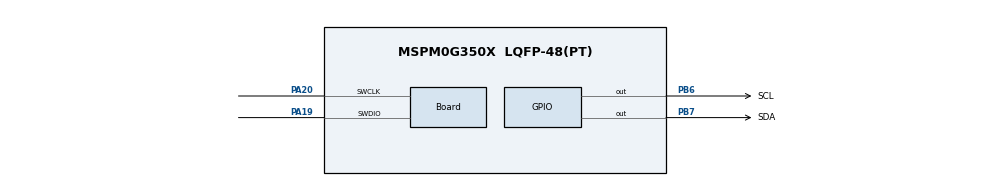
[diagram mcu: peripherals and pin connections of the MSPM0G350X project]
/**
 * @cliArgs --device "MSPM0G350X" --package "LQFP-48(PT)" --part "Default" --product "mspm0_sdk@2.01.00.03"
 * @versions {"tool":"1.20.0+3587"}
 */

/**
 * Import the modules used in this configuration.
 */
const GPIO          = scripting.addModule("/ti/driverlib/GPIO", {}, false);
const GPIO1         = GPIO.addInstance();
const GPIO2         = GPIO.addInstance();
const SYSCTL        = scripting.addModule("/ti/driverlib/SYSCTL");
const ProjectConfig = scripting.addModule("/ti/project_config/ProjectConfig");

/**
 * Write custom configuration values to the imported modules.
 */
GPIO1.$name                              = "GPIO_ENCODER";
GPIO1.associatedPins.create(2);
GPIO1.associatedPins[0].$name            = "PHASE_A";
GPIO1.associatedPins[0].direction        = "INPUT";
GPIO1.associatedPins[0].assignedPort     = "PORTA";
GPIO1.associatedPins[0].interruptEn      = true;
GPIO1.associatedPins[0].polarity         = "RISE_FALL";
GPIO1.associatedPins[0].assignedPin      = "26";
GPIO1.associatedPins[0].internalResistor = "PULL_UP";
GPIO1.associatedPins[1].$name            = "PHASE_B";
GPIO1.associatedPins[1].direction        = "INPUT";
GPIO1.associatedPins[1].assignedPort     = "PORTA";
GPIO1.associatedPins[1].interruptEn      = true;
GPIO1.associatedPins[1].polarity         = "RISE_FALL";
GPIO1.associatedPins[1].assignedPin      = "27";
GPIO1.associatedPins[1].internalResistor = "PULL_UP";

const Board                       = scripting.addModule("/ti/driverlib/Board", {}, false);
Board.peripheral.$assign          = "DEBUGSS";
Board.peripheral.swclkPin.$assign = "PA20";
Board.peripheral.swdioPin.$assign = "PA19";

GPIO2.$name                              = "GPIO_OLED";
GPIO2.associatedPins.create(2);
GPIO2.associatedPins[0].$name            = "SCL";
GPIO2.associatedPins[0].initialValue     = "SET";
GPIO2.associatedPins[0].assignedPort     = "PORTB";
GPIO2.associatedPins[0].assignedPin      = "6";
GPIO2.associatedPins[0].internalResistor = "PULL_UP";
GPIO2.associatedPins[0].pin.$assign      = "PB6";
GPIO2.associatedPins[1].$name            = "SDA";
GPIO2.associatedPins[1].initialValue     = "SET";
GPIO2.associatedPins[1].internalResistor = "PULL_UP";
GPIO2.associatedPins[1].assignedPort     = "PORTB";
GPIO2.associatedPins[1].assignedPin      = "7";
GPIO2.associatedPins[1].pin.$assign      = "PB7";

SYSCTL.forceDefaultClkConfig = true;
SYSCTL.peripheral.$assign    = "SYSCTL";

ProjectConfig.deviceSpin = "MSPM0G3507";

/**
 * Pinmux solution for unlocked pins/peripherals. This ensures that minor changes to the automatic solver in a future
 * version of the tool will not impact the pinmux you originally saw.  These lines can be completely deleted in order to
 * re-solve from scratch.
 */
GPIO1.associatedPins[0].pin.$suggestSolution = "PA26";
GPIO1.associatedPins[1].pin.$suggestSolution = "PA27";
